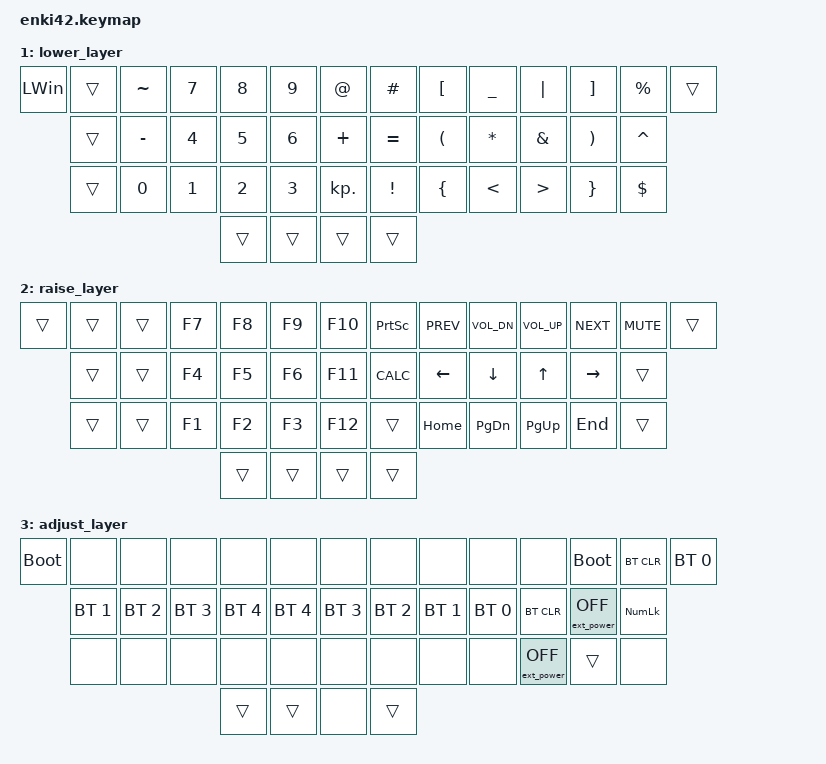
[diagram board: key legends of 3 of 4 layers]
/*
 * Copyright (c) 2020 The ZMK Contributors
 *
 * SPDX-License-Identifier: MIT
 */

#include <behaviors.dtsi>
#include <dt-bindings/zmk/bt.h>
#include <dt-bindings/zmk/ext_power.h>
#include <dt-bindings/zmk/keys.h>

#define DEF 0
#define LWR 1
#define RSE 2
#define ADJ 3

&mt {
    tapping-term-ms = <130>;
    flavor = "hold-preferred";
};

&lt {
    tapping-term-ms = <130>;
    flavor = "hold-preferred";
};

/ {
    macros {
        numdot: numdot {
            label = "ZM_numdot";
            compatible = "zmk,behavior-macro";
            #binding-cells = <0>;
            wait-ms = <40>;
            tap-ms = <40>;
            bindings =
                <&macro_press>,
                <&kp LALT>,
                <&macro_tap>,
                <&kp KP_N4 &kp KP_N6>,
                <&macro_release>,
                <&kp LALT>;
        };

        grtsgn: grtsgn {
            label = "ZM_grtsgn";
            compatible = "zmk,behavior-macro";
            #binding-cells = <0>;
            wait-ms = <40>;
            tap-ms = <40>;
            bindings =
                <&macro_press>,
                <&kp LALT>,
                <&macro_tap>,
                <&kp KP_N6 &kp KP_N2>,
                <&macro_release>,
                <&kp LALT>;
        };
    };
};

/ {
    keymap {
        compatible = "zmk,keymap";

        default_layer {
            // -----------------------------------------------------------------------------------------
            // |  GUI |   ~  |  Q  |  W  |  E  |  R  |  T  |   |  Y  |  U   |  I  |  O  |  P  |  [   | GUI/] |
            //        | CTRL |  A  |  S  |  D  |  F  |  G  |   |  H  |  J   |  K  |  L  |  ;  |CTRL/'|
            //        | LALT |  Z  |  X  |  C  |  V  |  B  |   |  N  |  M   |  ,  |  .  |  /  | RALT |
            //                           | RSE | SPC | LWR |   | LWR | BKSP | RSE |

            bindings = <
&kp LWIN  &kp ESC       &kp Q  &kp W  &kp E      &kp R      &kp T         &kp Y      &kp U          &kp I        &kp O    &kp P     &kp LEFT_BRACKET  &kp RIGHT_BRACKET
          &kp LCTRL     &kp A  &kp S  &kp D      &kp F      &kp G         &kp H      &kp J          &kp K        &kp L    &kp SEMI  &kp APOS
          &kp LEFT_ALT  &kp Z  &kp X  &kp C      &kp V      &kp B         &kp N      &kp M          &kp COMMA    &kp DOT  &kp FSLH  &kp BACKSLASH
                                      &lt 1 TAB  &kp SPACE  &kp LSHIFT    &kp ENTER  &kp BACKSPACE  &lt RSE DEL
            >;
        };

        lower_layer {
            // -----------------------------------------------------------------------------------------
            //|LGUI/CAPS |  *  |  7 |  8  |  9  |  +  |    |  !  |  @  |  #  |  $  |  %  | RGUI/F1 |
            //|CTRL/MENU |  /  |  4 |  5  |  6  |  -  |    |  ^  |  &  |  *  |  (  |  )  | CTRL/F2 |
            //|  LALT/=  |  0  |  1 |  4  |  3  |  .  |    |  ls |  F4 |  F5 |  F6 |  F7 | RALT/F3 |
            //                      | ADJ | ___ | ___ |    | ___ | ___ | ADJ |

            bindings = <
&kp LEFT_WIN  &trans  &kp TILDE  &kp N7  &kp N8  &kp N9  &kp AT        &kp HASH   &kp LEFT_BRACKET      &kp UNDER      &kp PIPE          &kp RIGHT_BRACKET      &kp PERCENT  &trans
              &trans  &kp MINUS  &kp N4  &kp N5  &kp N6  &kp PLUS      &kp EQUAL  &kp LEFT_PARENTHESIS  &kp STAR       &kp AMPS          &kp RIGHT_PARENTHESIS  &kp CARET
              &trans  &kp N0     &kp N1  &kp N2  &kp N3  &kp KP_DOT    &kp EXCL   &kp LEFT_BRACE        &kp LESS_THAN  &kp GREATER_THAN  &kp RIGHT_BRACE        &kp DOLLAR
                                         &trans  &trans  &trans        &trans
            >;
        };

        raise_layer {
            // -----------------------------------------------------------------------------------------
            //| LGUI |  VOLU  |  PGUP  | PLAY | HOME | ___  |            | ___  | HOME | PLAY| PGUP | VOLU | RGUI |
            //| CTRL |  VOLD  |  LEFT  |  UP  | DOWN | RGHT |            | RGHT | DOWN | UP  | LEFT | VOLD | CTRL | 
            //| LALT |  MUTE  |  PGDN  |  ___ | END  | ___  |            | ___  | END  | ___ | PGDN | MUTE | RALT |
            //                          | ___ | ___  | ADJ  |            | ADJ  | ___  | ___ |

            bindings = <
&trans  &trans  &trans  &kp F7  &kp F8  &kp F9  &kp F10    &kp PRINTSCREEN  &kp C_PREV  &kp C_VOL_DN    &kp C_VOLUME_UP  &kp K_NEXT  &kp K_MUTE  &trans
        &trans  &trans  &kp F4  &kp F5  &kp F6  &kp F11    &kp K_CALC       &kp LEFT    &kp DOWN_ARROW  &kp UP_ARROW     &kp RIGHT   &trans
        &trans  &trans  &kp F1  &kp F2  &kp F3  &kp F12    &trans           &kp HOME    &kp PAGE_DOWN   &kp PG_UP        &kp END     &trans
                                &trans  &trans  &trans     &trans
            >;
        };

        adjust_layer {
            // -----------------------------------------------------------------------------------------
            //| BLDR |     |     |     |     |     |   |     |     |     |     |     | BLDR |
            //| BTCLR| BT0 | BT1 | BT2 | BT3 | BT4 |   | BT4 | BT3 | BT2 | BT1 | BT0 | BTCLR|
            //|pwrOFF|NUMLK|     |     |     |     |   |     |     |     |     |     |      |
            //                   |     |     |     |   |     |     |     |

            bindings = <
&bootloader  &none         &none         &none         &none         &none         &none           &none         &none         &none         &none              &bootloader        &bt BT_CLR  &bt BT_SEL 0
             &bt BT_SEL 1  &bt BT_SEL 2  &bt BT_SEL 3  &bt BT_SEL 4  &bt BT_SEL 4  &bt BT_SEL 3    &bt BT_SEL 2  &bt BT_SEL 1  &bt BT_SEL 0  &bt BT_CLR         &ext_power EP_OFF  &kp KP_NUM
             &none         &none         &none         &none         &none         &none           &none         &none         &none         &ext_power EP_OFF  &trans             &none
                                                       &trans        &trans        &none           &trans
            >;
        };
    };
};
